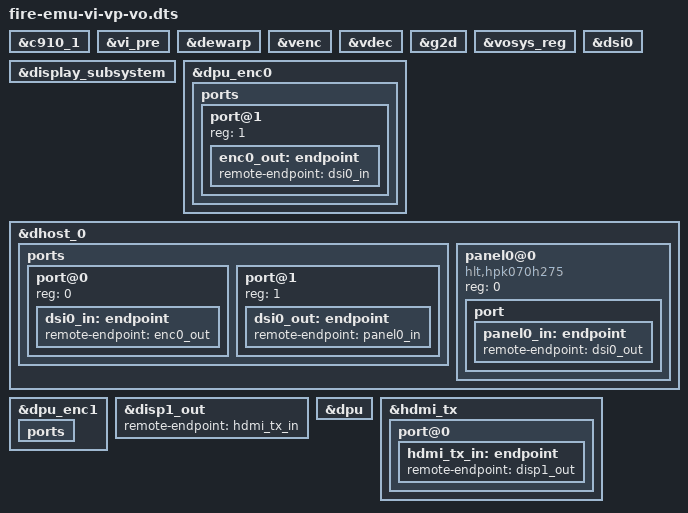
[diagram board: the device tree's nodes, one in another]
/* SPDX-License-Identifier: GPL-2.0 */
/*
 * Copyright (C) 2021-2022 Alibaba Group Holding Limited.
 */

/dts-v1/;

#include "fire-emu.dts"

&c910_1 {
	status = "okay";
};

&vi_pre {
	status = "okay";
};

&dewarp {
	status = "okay";
};

&venc {
	status = "okay";
};

&vdec {
	status = "okay";
};

&g2d {
	status = "okay";
};

&vosys_reg {
	status = "okay";
};

&display_subsystem {
	status = "okay";
};

&dpu_enc0 {
	status = "okay";

	ports {
		/* output */
		port@1 {
			reg = <1>;

			enc0_out: endpoint {
				remote-endpoint = <&dsi0_in>;
			};
		};
	};
};

&dsi0 {
	status = "okay";
};

&dhost_0 {
	ports {
		#address-cells = <1>;
		#size-cells = <0>;

		port@0 {
			reg = <0>;

			dsi0_in: endpoint {
				remote-endpoint = <&enc0_out>;
			};
		};

		port@1 {
			reg = <1>;

			dsi0_out: endpoint {
				remote-endpoint = <&panel0_in>;
			};
		};
	};

	panel0@0 {
		compatible = "hlt,hpk070h275";
		reg = <0>;

		port {
			panel0_in: endpoint {
				remote-endpoint = <&dsi0_out>;
			};
		};
	};
};

&dpu_enc1 {
	ports {
		/delete-node/ port@0;
	};
};

&disp1_out {
	remote-endpoint = <&hdmi_tx_in>;
};

&dpu {
	status = "okay";
};

&hdmi_tx {
	status = "okay";

	port@0 {
		/* input */
		hdmi_tx_in: endpoint {
			remote-endpoint = <&disp1_out>;
		};
	};
};

